# nrf54h20_enga_application register map
Vendor: Nordic Semiconductor; Series: nRF54h; File version: 1
CPU: CM33 r0p4, little endian, MPU, FPU, 3 interrupt priority bits, 480 interrupts, 4 SAU regions
Registers are 32-bit, read-write, reset 0x0 unless marked. A register's access mark holds for its fields unless they carry their own. Offsets are from the block's base; [hi:lo] are bit positions; lines under a group give offsets from that group; {n}, {i} and the like mark numbered series.

## ABB_S — ABB peripheral
Base 0x5201C000
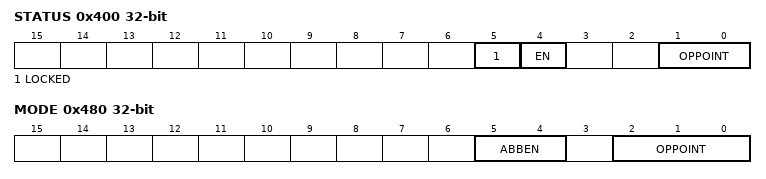
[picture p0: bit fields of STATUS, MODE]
0x400 STATUS ro — ABB status
  [5] LOCKED — The ABB lock status.
    0=NotLocked; 1=Locked
  [4] EN — The ABB enable status.
    0=Disabled (ABB disabled); 1=Enabled (ABB enabled)
  [1:0] OPPOINT — The current ABB operating point
    0=OpPoint0V4 (Operating point 0.4V); 1=OpPoint0V5 (Operating point 0.5V); 2=OpPoint0V6 (Operating point 0.6V); 3=OpPoint0V8 (Operating point 0.8V)
0x480 MODE — ABB control
  [5:4] ABBEN — Enable ABB.
    0=Auto (The peripheral controls the ABB enable automatically based on request.); 1=Enable (Force enable ABB); 2=Disable (Force disable ABB)
  [2:0] OPPOINT — The ABB operating point.
    0=Auto (The peripheral controls the operating point automatically based on request from the master ABB controller.); 1=OpPoint0V4 (Force the operating point to 0.4V); 2=OpPoint0V5 (Force the operating point to 0.5V); 3=OpPoint0V6 (Force the operating point to 0.6V); 4=OpPoint0V8 (Force the operating point to 0.8V)

## RESETINFO_S — RESETINFO
Base 0x5201E000; alternate view of LRCCONF010_S
0x4A0 RESETREAS group — Unspecified
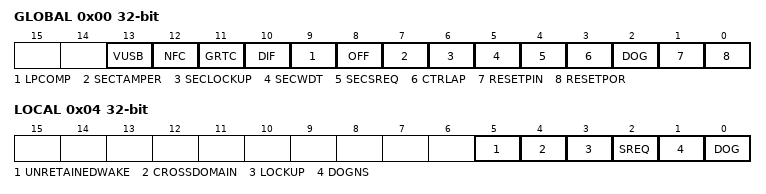
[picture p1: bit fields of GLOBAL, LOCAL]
  0x00 GLOBAL — Global reset reason.
    [all] fields
      0=NotDetected; 1=Detected
    [13] VUSB — Reset after wakeup from System OFF mode due to VBUS rising into valid range.
    [12] NFC — Reset due to wakeup from System OFF mode when wakeup is triggered by NFC field detection in sense mode.
    [11] GRTC — Reset due to wakeup from System OFF mode when wakeup is triggered by GRTC interrupt.
    [10] DIF — Reset due to wakeup from System OFF mode when wakeup is triggered by entering the debug interface mode.
    [9] LPCOMP — Reset due to wakeup from System OFF mode when wakeup is triggered by LPCOMP (Low Power Comparator).
    [8] OFF — Reset due to wakeup from System OFF mode when wakeup is triggered by DETECT signal from GPIO.
    [7] SECTAMPER — Reset due to secure domain tamper detected
    [6] SECLOCKUP — Reset due to secure domain lockup.
    [5] SECWDT — Reset due to secure domain watchdog timer detected.
    [4] SECSREQ — Reset due to secure domain system reset request.
    [3] CTRLAP — Reset from CTRL-AP detected.
    [2] DOG — Reset from the SysCtrl watchdog timer detected.
    [1] RESETPIN — Reset from pin reset detected.
    [0] RESETPOR — Reset from power on reset.
  0x04 LOCAL — Local reset reason.
    [5] UNRETAINEDWAKE — Reset due to wake from unretained state.
    [4] CROSSDOMAIN — Reset due to cross domain reset source.
      0=NotDetected; 1=Detected
    [3] LOCKUP — Reset from local CPU lockup detected
      0=NotDetected; 1=Detected
    [2] SREQ — Reset from the local soft reset request detected.
      0=NotDetected; 1=Detected
    [1] DOGNS — Reset from the local non-secure watchdog timer detected
      0=NotDetected; 1=Detected
    [0] DOG — Reset from the local watchdog timer detected
      0=NotDetected; 1=Detected
  0x08 ERROR group — Unspecified
    0x00 STATUS — Reset error status.
      [3:0] ERRORSTATUS
    0x04 ADDRESS — Reset error address.
      [31:0] ERRORADDRESS
0x4C0 RESTOREVALID write-1-clears — Valid restore image is present in RAM.
  [0] RESTOREVALID
    0=NotPreset (Not present); 1=Present

## BELLBOARD_NS — BELLBOARD APB registers 0
Base 0x4F09A000
Same registers: BELLBOARD_S 0x5F09A000
{0x0+4i} TASKS_TRIGGER[{i}] (i=0..31) wo — Description collection: Task TRIGGER[n]
  [0] TASKS_TRIGGER — Task TRIGGER[n]
    1=Trigger task
{0x100+4i} EVENTS_TRIGGERED[{i}] (i=0..31) — Description collection: Event TRIGGERED[n]
  [0] EVENTS_TRIGGERED — Event TRIGGERED[n]
    0=NotGenerated (Event not generated); 1=Generated (Event generated)
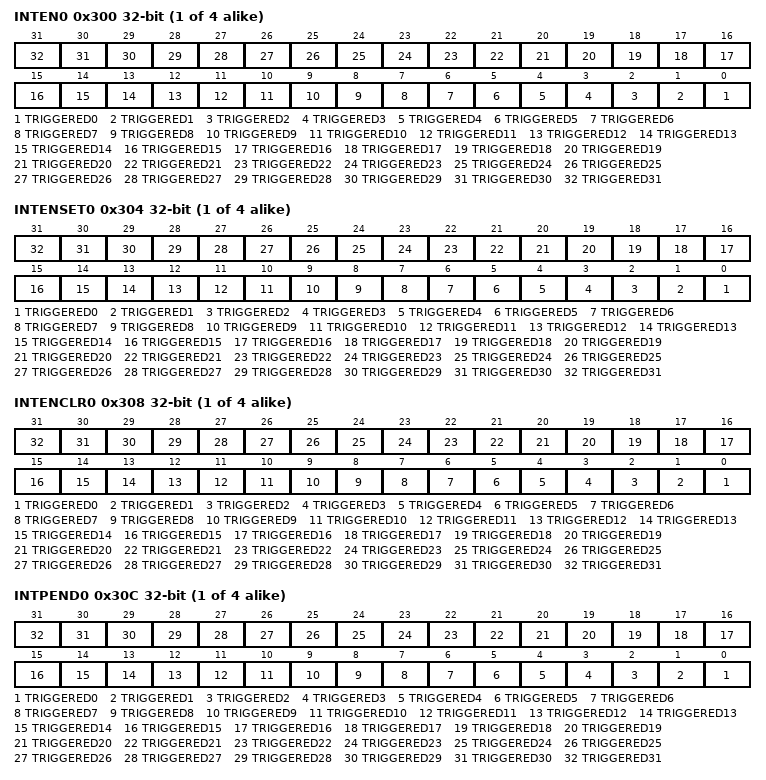
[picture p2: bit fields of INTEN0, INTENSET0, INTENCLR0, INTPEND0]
{0x300+0x10*i} INTEN{i} (i=0..3) — Enable or disable interrupt
  [all] fields
    0=Disabled; 1=Enabled
  [n] TRIGGERED{n} (n=0..31) — Enable or disable interrupt for event TRIGGERED[{n}]
{0x304+0x10*i} INTENSET{i} (i=0..3) — Enable interrupt
  [all] fields
    on read: 0=Disabled (Read: Disabled); 1=Enabled (Read: Enabled) | on write: 1=Set (Enable)
  [n] TRIGGERED{n} (n=0..31) — Write '1' to enable interrupt for event TRIGGERED[{n}]
{0x308+0x10*i} INTENCLR{i} (i=0..3) — Disable interrupt
  [all] fields
    on read: 0=Disabled (Read: Disabled); 1=Enabled (Read: Enabled) | on write: 1=Clear (Disable)
  [n] TRIGGERED{n} (n=0..31) — Write '1' to disable interrupt for event TRIGGERED[{n}]
{0x30C+0x10*i} INTPEND{i} ro (i=0..3) — Pending interrupts
  [all] fields
    on read: 0=NotPending (Read: Not pending); 1=Pending (Read: Pending)
  [n] TRIGGERED{n} (n=0..31) — Read pending status of interrupt for event TRIGGERED[{n}]
